# ipro6s register map
Vendor: intelpro; Series: IPRO6S
CPU: ipro6s, little endian
Registers are 32-bit, read-write, reset 0x0 unless marked. A register's access mark holds for its fields unless they carry their own. Offsets are from the block's base; [hi:lo] are bit positions.

## HBN
Base 0x3008F000
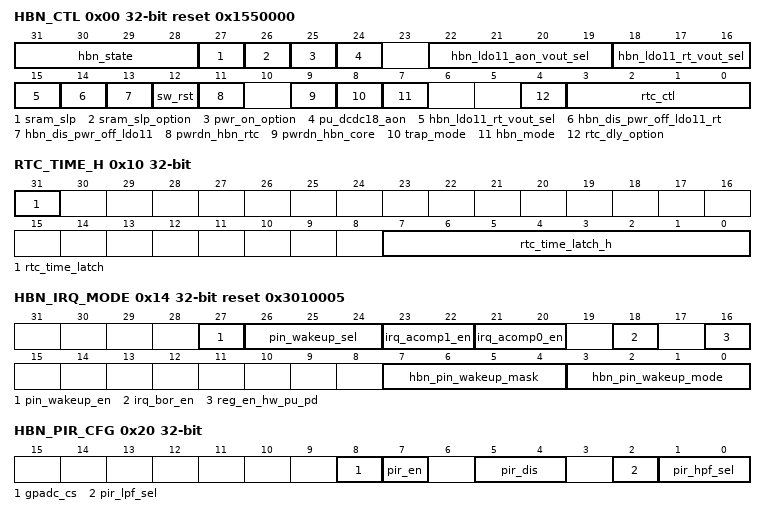
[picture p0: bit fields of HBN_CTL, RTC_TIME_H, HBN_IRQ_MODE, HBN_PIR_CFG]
0x00 HBN_CTL reset 0x1550000 (reset mask 0x77FFA9F)
  [31:28] hbn_state ro — SW polling until 0 (default 4'h3 @pwron)
  [27] sram_slp ro — SW polling until 0 (default 1'b1 @pwron)
  [26] sram_slp_option
  [25] pwr_on_option
  [24] pu_dcdc18_aon — Power On DCDC18 during Power On Sequence (require 400~800us)
  [22:19] hbn_ldo11_aon_vout_sel — VDD11_AON Voltage Out Select @ Enter hibernate
  [18:15] hbn_ldo11_rt_vout_sel — VDD11_RT Voltage Out Select @ Enter hibernate
  [14] hbn_dis_pwr_off_ldo11_rt — Set 1 to disable power off VDDCORE_RT at HBN mode (for low power)
  [13] hbn_dis_pwr_off_ldo11 — Set 1 to disable power off VDDCORE at HBN mode (for debug)
  [12] sw_rst — soft reset
  [11] pwrdn_hbn_rtc — Power Off HBN RTC @ Enter hibernate
  [9] pwrdn_hbn_core — Power Off HBN Core @ Enter hibernate
  [8] trap_mode ro — Boot Strap 0: Flash, 1: UART or SDIO
  [7] hbn_mode wo — Enter hibernate
  [4] rtc_dly_option
  [3:0] rtc_ctl — [6:4] Slow LED, x/0.25/0.5/1/2/4/8/16 seconds (move to 0x38) [3] rtc long time 0~353days (bit 39~13 compare) [2] rtc short time 0~488s (bit 23~0 compare) [1] rtc time 0~353days (bit 39~0 compare) [0] rtc enable
0x04 HBN_TIME_L
  [31:0] hbn_time_l — RTC timer compare bit 31:0
0x08 HBN_TIME_H
  [7:0] hbn_time_h — RTC timer compare bit 39:32
0x0C RTC_TIME_L reset not defined
  [31:0] rtc_time_latch_l ro — RTC time latched value bit 31:0
0x10 RTC_TIME_H (reset mask 0x80000000)
  [31] rtc_time_latch wo — RTC time latch for SW read
  [7:0] rtc_time_latch_h ro — RTC time latched value bit 39:32
0x14 HBN_IRQ_MODE reset 0x3010005
  [27] pin_wakeup_en — Pin wakeup delay enable
  [26:24] pin_wakeup_sel — Pin wakeup delay 1~7 sec
  [23:22] irq_acomp1_en — enable acomp1 interrupt [20] posedge [21] negedge
  [21:20] irq_acomp0_en — enable acomp0 interrupt [20] posedge [21] negedge
  [18] irq_bor_en — enable brown-out interrupt
  [16] reg_en_hw_pu_pd — 1: Pull GPIO17 @ pwr_on and pwr_rst 0 : no pull
  [7:4] hbn_pin_wakeup_mask — mask hbn_pin_wakeup_event
  [3:0] hbn_pin_wakeup_mode — hbn_pin_wakeup mode 0000 : sync falling edge trigger 0001 : sync rising edge trigger 0010 : sync low level trigger 0011 : sync high level trigger 01xx : sync rising & falling edge trigger 1000 : async falling edge trigger 1001 : async rising edge trigger 1010 : async low level trigger 1011 : async high level trigger
0x18 HBN_IRQ_STAT reset not defined
  [31:0] irq_stat ro — [22] acomp1 [20] acomp0 [18] brown-out [17] irq_pir state [16] irq_rtc state [3:0] hbn_pin_wakeup state (GPIO19/18/17/16)
0x1C HBN_IRQ_CLR
  [31:0] irq_clr wo — [22] irq_acomp1 clear [20] irq_acomp0 clear [18] irq_bor clear [17] irq_pir clear [16] irq_rtc clear [3:0] hbn_pin_wakeup state (GPIO19/18/17/16)
0x20 HBN_PIR_CFG
  [8] gpadc_cs — GPADC clock source select signal 0: 32MHz clock 1: PIR clock (f32k_clk)
  [7] pir_en — pir enable
  [5:4] pir_dis — pir disable [4] low -> high won't trigger interrupt [5] high -> low won't trigger interrupt
  [2] pir_lpf_sel — 0: /1. 1:/2
  [1:0] pir_hpf_sel — 0: 1-z^-1, 1: 1-z^-2, 0: 2-z^-3
0x24 HBN_PIR_VTH reset 0x3FF
  [13:0] pir_vth — PIR compare threshold
0x28 HBN_PIR_INTERVAL reset 0xA3D
  [11:0] pir_interval — pir_lpf_sel = 0: 32768 / (pir_interval+1) Hz, default 12.5Hz (~80ms) pir_lpf_sel = 1: 32768 / (pir_interval*2+1) Hz, default 6.25Hz (~160ms)
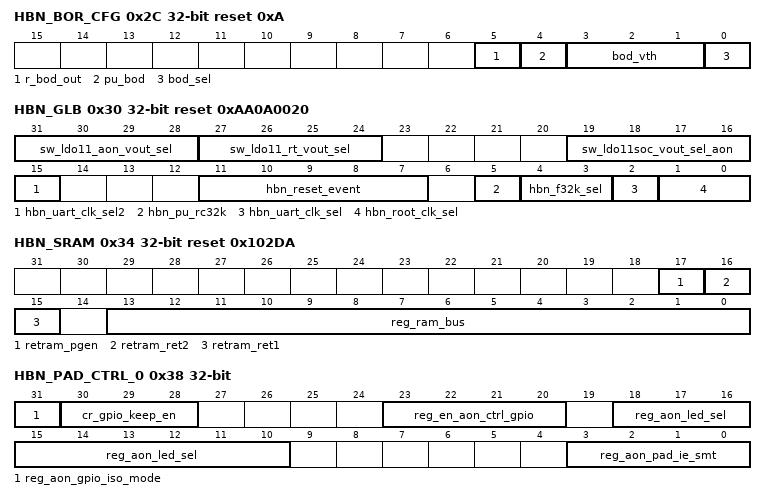
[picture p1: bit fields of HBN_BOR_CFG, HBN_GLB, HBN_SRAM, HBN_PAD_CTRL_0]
0x2C HBN_BOR_CFG reset 0xA (reset mask 0x1F)
  [5] r_bod_out ro
  [4] pu_bod — Power up Brown Out Reset
  [3:1] bod_vth — bod threshold 000: 2.05V, 001: 2.10V, 010: 2.15V, 011: 2.20V, 100: 2.25V, 101: 2.30V, 110: 2.35V, 111: 2.40V
  [0] bod_sel — 0: POR is independent of BOD, 1: POR is relevant to BOD
0x30 HBN_GLB reset 0xAA0A0020 (reset mask 0xFF0F803F)
  [31:28] sw_ldo11_aon_vout_sel — aon ldo output voltage external control: 0:0.70V, 1:0.70V, 2:0.70V, 3:0.75V, 4:0.80V, 5:0.85V, 6:0.9V, 7:0.95V 8:1.0V, 9:1.05V, 10:1.1V, 11:1.15V, 12:1.2V, 13:1.25V, 14:1.3V, 15:1.35V
  [27:24] sw_ldo11_rt_vout_sel — ldo output voltage external control: 0:0.70V, 1:0.70V, 2:0.70V, 3:0.75V, 4:0.80V, 5:0.85V, 6:0.9V, 7:0.95V 8:1.0V, 9:1.05V, 10:1.1V, 11:1.15V, 12:1.2V, 13:1.25V, 14:1.3V, 15:1.35V
  [19:16] sw_ldo11soc_vout_sel_aon — vdd11soc output voltage selection
  [15] hbn_uart_clk_sel2 — UART clock selection2 from HBN (0 : result of hbn_uart_clk_sel (bclk or MUX 160MHz), 1: XCLK (XTAL or RC32M))
  [11:7] hbn_reset_event ro — [4] : bor_out_ event [3] : pwr_rst_n event [2] : sw_rst event [1] : por_out event [0] : watch dog reset
  [5] hbn_pu_rc32k — 0: Turn off rc32k during rtc power domain off, 1: Don't turn off rc32k (move to RTC Domain)
  [4:3] hbn_f32k_sel — 32KHz clock source selection (0: RC32K 1: XTAL 32K 3: DIG 32K)
  [2] hbn_uart_clk_sel — UART clock selection from HBN (0:bclk 1:muxpll_160m_clk)
  [1:0] hbn_root_clk_sel — root clock source selection (0: RC32M 1: XTAL 2/3: PLL)
0x34 HBN_SRAM reset 0x102DA
  [17] retram_pgen — make HBN RAM Sleep
  [16] retram_ret2 — make HBN RAM Retention
  [15] retram_ret1 — make HBN RAM Nap
  [13:0] reg_ram_bus — [13:12]=ram_bus[22:21]=WABLM_RF [11:10]=ram_bus[20:19]=RAWLM [9]=ram_bus[18]=WABL [8]=ram_bus[17]=RAWL [7:6]=ram_bus[16:15]=EMAW [5:3]=ram_bus[14:12]=EMA_RF [2:0]=ram_bus[11:9]=EMA_ROM
0x38 HBN_PAD_CTRL_0
  [31] reg_aon_gpio_iso_mode — 1: HW Keep GPIO @ PDS or HBN Mode 0 : No Keep GPIO @ PDS or HBN Mode
  [30:28] cr_gpio_keep_en — if cr_aon_ctrl_gpio_latch=1, can use bit to enable or disable IO latch function at enter HBN Mode [0] : GPIO0~15 [1] : GPIO20~36 [2] : GPIO16~19
  [23:20] reg_en_aon_ctrl_gpio — AON GPIO16~19 Control by AON HW : [23] :GPIO19 [22]: GPIO18 [21]: GPIO17(can be muxed to be XTAL32K) [20]: GPIO16(can be muxed to be XTAL32K)
  [18:10] reg_aon_led_sel — (if corresponding AON GPIO controlled by AON HW) Always on PAD Output Slow LED, x/0.25/0.5/1/2/4/8/16 seconds [12:10] (for GPIO16) : reg_aon_led1_sel [15:13] (for GPIO17) : reg_aon_led2_sel [18:16] (for GPIO18/19) : reg_aon_led3_sel 1 : 0.25sec 2 : 0.5sec 3: 1 sec 4: 2sec 5: 4 sec 6 : 8sec 7 :16sec
  [3:0] reg_aon_pad_ie_smt — Always on PAD IE/SMT (if corresponding AON GPIO controlled by AON HW) [3] : GPIO19 [2] : GPIO18 [1] : GPIO17 [0] : GPIO16
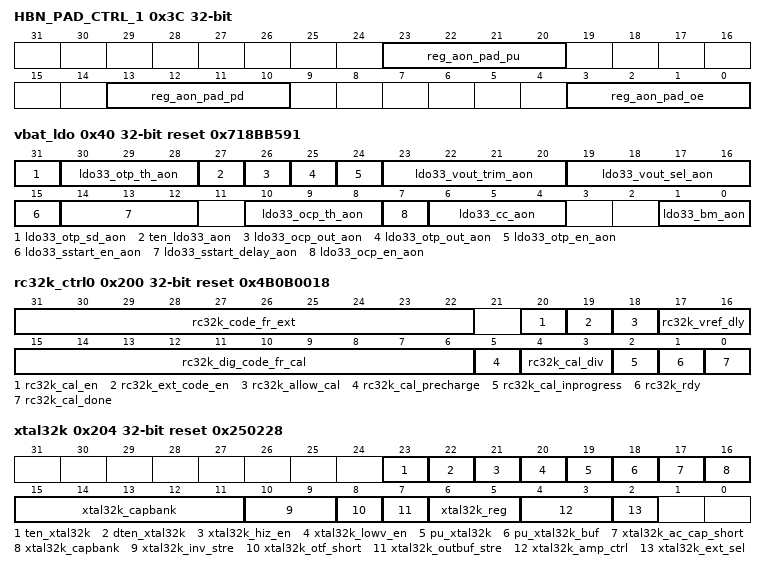
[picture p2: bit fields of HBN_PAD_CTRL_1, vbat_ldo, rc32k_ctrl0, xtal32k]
0x3C HBN_PAD_CTRL_1
  [23:20] reg_aon_pad_pu — Always on PAD PU (if corresponding AON GPIO controlled by AON HW) [23] : GPIO19 [22] : GPIO18 [21] : GPIO17 [20] : GPIO16
  [13:10] reg_aon_pad_pd — Always on PAD PD (if corresponding AON GPIO controlled by AON HW) [13] : GPIO19 [12] : GPIO18 [11] : GPIO17 [10] : GPIO16
  [3:0] reg_aon_pad_oe — Always on PAD OE (if corresponding AON GPIO controlled by AON HW) [3] : GPIO19 [2] : GPIO18 [1] : GPIO17 [0] : GPIO16
0x40 vbat_ldo reset 0x718BB591 (reset mask 0xF9FFF7F3)
  [31] ldo33_otp_sd_aon — 0: donot pulldown ldo33 when OTP happens, 1: pulldown ldo33 when OTP happens
  [30:28] ldo33_otp_th_aon — OTP temperature threshold selection: 0: 125C, 1: 150C, 2: 175C, 3: 200C, 4: 200C, . 7: 200C
  [27] ten_ldo33_aon
  [26] ldo33_ocp_out_aon ro — OCP signal
  [25] ldo33_otp_out_aon ro — OTP signal
  [24] ldo33_otp_en_aon — enable Over Temperature Protection circuit in vbat_top
  [23:20] ldo33_vout_trim_aon — output voltage trim: 1% per step 0: 91%, . 7: 99%, 8: 100%, 9: 101%, . f: 108%
  [19:16] ldo33_vout_sel_aon — avdd33_out voltage selection: 0: 2.10, 1: 2.20, 2: 2.30, 3: 2.40, 4: 2.50, 5: 2.70, 6: 2.90, 7: 3.00, 8: 3.10, 9: 3.20, a: 3.25, b: 3.30, c: 3.35, d: 3.40, e: 3.50, f: 3.60
  [15] ldo33_sstart_en_aon — enable Soft-start circuit in vbat_top
  [14:12] ldo33_sstart_delay_aon — Sstart time selection: 0: 200us, 1: 290us, 2: 390us, 3: 480us, 4: 580us, 5: 670us, 6: 770us, 7: 860us
  [10:8] ldo33_ocp_th_aon — OCP current threshold selection: 0: 0.5A, 1: 0.6A, 2: 0.8A, 3: 1.0A, 4: 1.2A, 5: 1.5A, 6: 2.0A, 7: 2.0A
  [7] ldo33_ocp_en_aon — enable Over Current Protection circuit in vbat_top
  [6:4] ldo33_cc_aon — Compensation Capacitance selection
  [1:0] ldo33_bm_aon — Bias mode selection
0x100 HBN_RSV0
  [31:0] HBN_RSV0 — SW use for wakeup flag
0x104 HBN_RSV1 reset 0xFFFFFFFF
0x108 HBN_RSV2
0x10C HBN_RSV3 reset 0xFFFFFFFF
0x200 rc32k_ctrl0 reset 0x4B0B0018 (reset mask 0xFFDF0018)
  [31:22] rc32k_code_fr_ext — External code In for frequency setting
  [20] rc32k_cal_en — Enable calibration of 32k oscillator
  [19] rc32k_ext_code_en — Allow external code in to go into the ckt
  [18] rc32k_allow_cal — Allow calibration to be performed (monitor system clock)
  [17:16] rc32k_vref_dly — reference power up delay
  [15:6] rc32k_dig_code_fr_cal ro — After calibration hold calibrated code
  [5] rc32k_cal_precharge ro — Initial a new cal
  [4:3] rc32k_cal_div — Divider for the clock step during calibration
  [2] rc32k_cal_inprogress ro — Asserts high when calibration is in progress
  [1] rc32k_rdy ro — Asserts high when 32k clock is ready upon pwrup
  [0] rc32k_cal_done ro — Asserts high when calibration is done
0x204 xtal32k reset 0x250228
  [23] ten_xtal32k
  [22] dten_xtal32k
  [21] xtal32k_hiz_en — high-z xtal32k input/output for share gpio usage
  [20] xtal32k_lowv_en — xtal32k low voltage mode enable
  [19] pu_xtal32k — power up signal for 32K crystal oscillator
  [18] pu_xtal32k_buf — 1: power up XTAL32k level shifter buffer
  [17] xtal32k_ac_cap_short
  [16:11] xtal32k_capbank — 32K crystal load cap control word (also copy from efuse)
  [10:9] xtal32k_inv_stre — 32K crystal inverter amplify strength
  [8] xtal32k_otf_short — 32K crystal over tone filter short
  [7] xtal32k_outbuf_stre — 32K crystal output buffer strength
  [6:5] xtal32k_reg — 32K crystal voltage regulator level
  [4:3] xtal32k_amp_ctrl — 32K crystal oscillation amplitude control
  [2] xtal32k_ext_sel — External 32K clock enable
